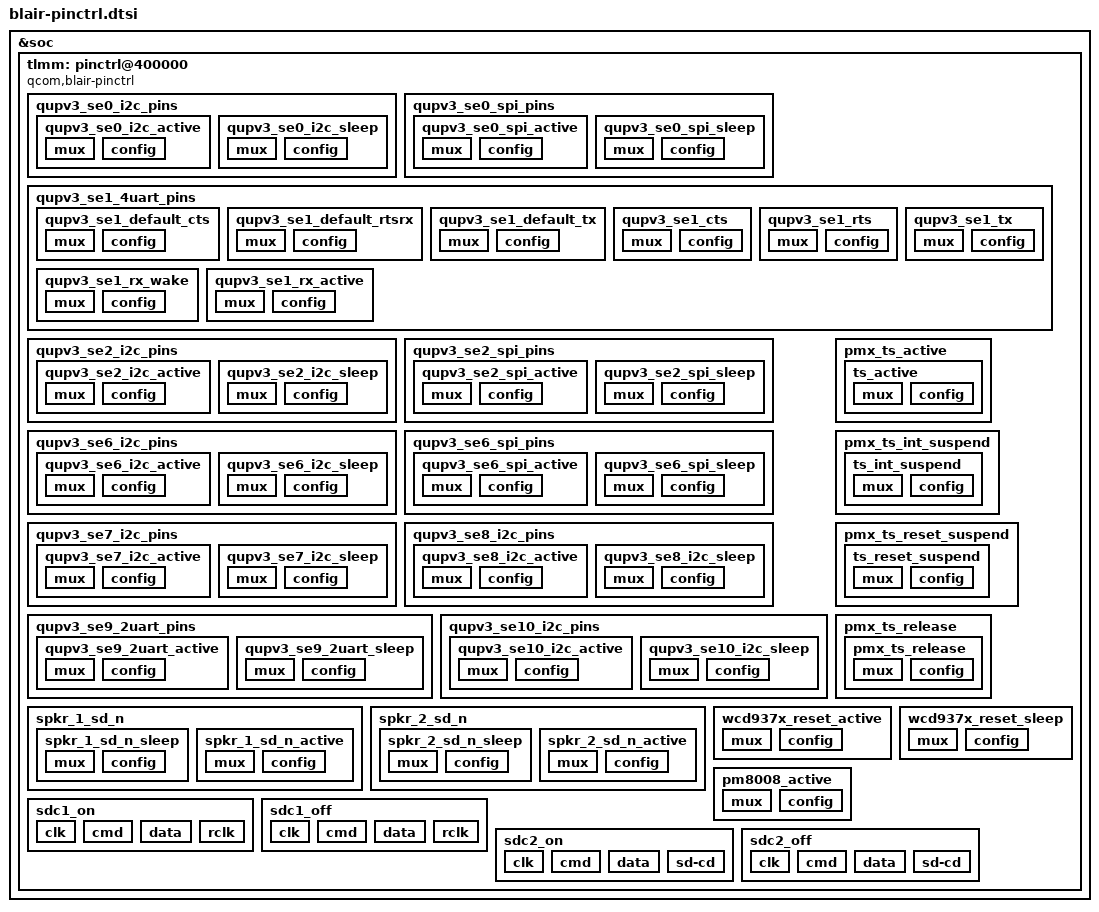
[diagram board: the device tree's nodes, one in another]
&soc {
	tlmm: pinctrl@400000 {
		compatible = "qcom,blair-pinctrl";
		reg = <0x400000 0x800000>;
		interrupts = <GIC_SPI 227 IRQ_TYPE_LEVEL_HIGH>;
		gpio-controller;
		#gpio-cells = <2>;
		interrupt-controller;
		#interrupt-cells = <2>;
		qcom,gpios-reserved = <13 14 15 16 17 45 46 48 56 57>;
		wakeup-parent = <&mpm>;

		qupv3_se0_i2c_pins: qupv3_se0_i2c_pins {
			qupv3_se0_i2c_active: qupv3_se0_i2c_active {
				mux {
					pins = "gpio0", "gpio1";
					function = "qup00";
				};

				config {
					pins = "gpio0", "gpio1";
					drive-strength = <2>;
					bias-pull-up;
				};
			};

			qupv3_se0_i2c_sleep: qupv3_se0_i2c_sleep {
				mux {
					pins = "gpio0", "gpio1";
					function = "gpio";
				};

				config {
					pins = "gpio0", "gpio1";
					drive-strength = <2>;
					bias-disable;
				};
			};
		};

		qupv3_se0_spi_pins: qupv3_se0_spi_pins {
			qupv3_se0_spi_active: qupv3_se0_spi_active {
				mux {
					pins = "gpio0", "gpio1",
							"gpio2", "gpio3";
					function = "qup00";
				};

				config {
					pins = "gpio0", "gpio1",
							"gpio2", "gpio3";
					drive-strength = <6>;
					bias-disable;
				};
			};

			qupv3_se0_spi_sleep: qupv3_se0_spi_sleep {
				mux {
					pins = "gpio0", "gpio1",
							"gpio2", "gpio3";
					function = "gpio";
				};

				config {
					pins = "gpio0", "gpio1",
							"gpio2", "gpio3";
					drive-strength = <2>;
					bias-disable;
				};
			};
		};

		qupv3_se1_4uart_pins: qupv3_se1_4uart_pins {
			qupv3_se1_default_cts:
				qupv3_se1_default_cts {
				mux {
					pins = "gpio61";
					function = "gpio";
				};

				config {
					pins = "gpio61";
					drive-strength = <2>;
					bias-pull-down;
				};
			};

			qupv3_se1_default_rtsrx:
				qupv3_se1_default_rtsrx {
				mux {
					pins = "gpio62", "gpio64";
					function = "gpio";
				};

				config {
					pins = "gpio62", "gpio64";
					drive-strength = <2>;
					bias-pull-down;
				};
			};

			qupv3_se1_default_tx:
				qupv3_se1_default_tx {
				mux {
					pins = "gpio63";
					function = "gpio";
				};

				config {
					pins = "gpio63";
					drive-strength = <2>;
					bias-pull-up;
				};
			};

			qupv3_se1_cts: qupv3_se1_cts {
				mux {
					pins = "gpio61";
					function = "qup01";
				};

				config {
					pins = "gpio61";
					drive-strength = <2>;
					bias-disable;
				};
			};

			qupv3_se1_rts: qupv3_se1_rts {
				mux {
					pins = "gpio62";
					function = "qup01";
				};

				config {
					pins = "gpio62";
					drive-strength = <2>;
					bias-pull-down;
				};
			};

			qupv3_se1_tx: qupv3_se1_tx {
				mux {
					pins = "gpio63";
					function = "qup01";
				};

				config {
					pins = "gpio63";
					drive-strength = <2>;
					bias-pull-up;
				};
			};

			/* RX to be in gpio mode for sleep config */
			qupv3_se1_rx_wake: qupv3_se1_rx_wake {
				mux {
					pins = "gpio64";
					function = "gpio";
				};

				config {
					pins = "gpio64";
					drive-strength = <2>;
					bias-disable;
				};
			};

			qupv3_se1_rx_active: qupv3_se1_rx_active {
				mux {
					pins = "gpio64";
					function = "qup01";
				};

				config {
					pins = "gpio64";
					drive-strength = <2>;
					bias-disable;
				};
			};
		};

		qupv3_se2_i2c_pins: qupv3_se2_i2c_pins {
			qupv3_se2_i2c_active: qupv3_se2_i2c_active {
				mux {
					pins = "gpio45", "gpio46";
					function = "qup02";
				};

				config {
					pins = "gpio45", "gpio46";
					drive-strength = <2>;
					bias-pull-up;
				};
			};

			qupv3_se2_i2c_sleep: qupv3_se2_i2c_sleep {
				mux {
					pins = "gpio45", "gpio46";
					function = "gpio";
				};

				config {
					pins = "gpio45", "gpio46";
					drive-strength = <2>;
					bias-disable;
				};
			};
		};

		qupv3_se2_spi_pins: qupv3_se2_spi_pins {
			qupv3_se2_spi_active: qupv3_se2_spi_active {
				mux {
					pins = "gpio45", "gpio46",
							"gpio56", "gpio57";
					function = "qup02";
				};

				config {
					pins = "gpio45", "gpio46",
							"gpio56", "gpio57";
					drive-strength = <6>;
					bias-disable;
				};
			};

			qupv3_se2_spi_sleep: qupv3_se2_spi_sleep {
				mux {
					pins = "gpio45", "gpio46",
							"gpio56", "gpio57";
					function = "gpio";
				};

				config {
					pins = "gpio45", "gpio46",
							"gpio56", "gpio57";
					drive-strength = <2>;
					bias-disable;
				};
			};
		};

		qupv3_se6_i2c_pins: qupv3_se6_i2c_pins {
			qupv3_se6_i2c_active: qupv3_se6_i2c_active {
				mux {
					pins = "gpio13", "gpio14";
					function = "qup10";
				};

				config {
					pins = "gpio13", "gpio14";
					drive-strength = <2>;
					bias-pull-up;
				};
			};

			qupv3_se6_i2c_sleep: qupv3_se6_i2c_sleep {
				mux {
					pins = "gpio13", "gpio14";
					function = "gpio";
				};

				config {
					pins = "gpio13", "gpio14";
					drive-strength = <2>;
					bias-disable;
				};
			};
		};

		qupv3_se6_spi_pins: qupv3_se6_spi_pins {
			qupv3_se6_spi_active: qupv3_se6_spi_active {
				mux {
					pins = "gpio13", "gpio14",
							"gpio15", "gpio16";
					function = "qup10";
				};

				config {
					pins = "gpio13", "gpio14",
							"gpio15", "gpio16";
					drive-strength = <6>;
					bias-disable;
				};
			};

			qupv3_se6_spi_sleep: qupv3_se6_spi_sleep {
				mux {
					pins = "gpio13", "gpio14",
							"gpio15", "gpio16";
					function = "gpio";
				};

				config {
					pins = "gpio13", "gpio14",
							"gpio15", "gpio16";
					drive-strength = <2>;
					bias-disable;
				};
			};
		};

		qupv3_se7_i2c_pins: qupv3_se7_i2c_pins {
			qupv3_se7_i2c_active: qupv3_se7_i2c_active {
				mux {
					pins = "gpio27", "gpio28";
					function = "qup11_f1";
				};

				config {
					pins = "gpio27", "gpio28";
					drive-strength = <2>;
					bias-pull-up;
				};
			};

			qupv3_se7_i2c_sleep: qupv3_se7_i2c_sleep {
				mux {
					pins = "gpio27", "gpio28";
					function = "gpio";
				};

				config {
					pins = "gpio27", "gpio28";
					drive-strength = <2>;
					bias-disable;
				};
			};
		};

		qupv3_se8_i2c_pins: qupv3_se8_i2c_pins {
			qupv3_se8_i2c_active: qupv3_se8_i2c_active {
				mux {
					pins = "gpio19", "gpio20";
					function = "qup12";
				};

				config {
					pins = "gpio19", "gpio20";
					drive-strength = <2>;
					bias-pull-up;
				};
			};

			qupv3_se8_i2c_sleep: qupv3_se8_i2c_sleep {
				mux {
					pins = "gpio19", "gpio20";
					function = "gpio";
				};

				config {
					pins = "gpio19", "gpio20";
					drive-strength = <2>;
					bias-disable;
				};
			};
		};

		qupv3_se9_2uart_pins: qupv3_se9_2uart_pins {
			qupv3_se9_2uart_active: qupv3_se9_2uart_active {
				mux {
					pins = "gpio25", "gpio26";
					function = "qup13_f2";
				};

				config {
					pins = "gpio25", "gpio26";
					drive-strength = <2>;
					bias-disable;
				};
			};

			qupv3_se9_2uart_sleep: qupv3_se9_2uart_sleep {
				mux {
					pins = "gpio25", "gpio26";
					function = "gpio";
				};

				config {
					pins = "gpio25", "gpio26";
					drive-strength = <2>;
					bias-pull-down;
				};
			};
		};

		qupv3_se10_i2c_pins: qupv3_se10_i2c_pins {
			qupv3_se10_i2c_active: qupv3_se10_i2c_active {
				mux {
					pins = "gpio4", "gpio5";
					function = "qup14";
				};

				config {
					pins = "gpio4", "gpio5";
					drive-strength = <2>;
					bias-pull-up;
				};
			};

			qupv3_se10_i2c_sleep: qupv3_se10_i2c_sleep {
				mux {
					pins = "gpio4", "gpio5";
					function = "gpio";
				};

				config {
					pins = "gpio4", "gpio5";
					drive-strength = <2>;
					bias-disable;
				};
			};
		};

		pmx_ts_active {
			ts_active: ts_active {
				mux {
					pins = "gpio21", "gpio22";
					function = "gpio";
				};

				config {
					pins = "gpio21", "gpio22";
					drive-strength = <8>;
					bias-pull-up;
				};
			};
		};

		pmx_ts_int_suspend {
			ts_int_suspend: ts_int_suspend {
				mux {
					pins = "gpio22";
					function = "gpio";
				};

				config {
					pins = "gpio22";
					drive-strength = <2>;
					bias-pull-down;
				};
			};
		};

		pmx_ts_reset_suspend {
			ts_reset_suspend: ts_reset_suspend {
				mux {
					pins = "gpio21";
					function = "gpio";
				};

				config {
					pins = "gpio21";
					drive-strength = <2>;
					bias-pull-down;
				};
			};
		};

		pmx_ts_release {
			pmx_ts_release: pmx_ts_release {
				mux {
					pins = "gpio21", "gpio22";
					function = "gpio";
				};

				config {
					pins = "gpio21", "gpio22";
					drive-strength = <2>;
					bias-disable;
				};
			};
		};

		/* WSA speaker reset pin */

		spkr_1_sd_n {
			spkr_1_sd_n_sleep: spkr_1_sd_n_sleep {
				mux {
					pins = "gpio86";
					function = "gpio";
				};

				config {
					pins = "gpio86";
					drive-strength = <2>;   /* 2 mA */
					bias-pull-down;
					input-enable;
				};
			};

			spkr_1_sd_n_active: spkr_1_sd_n_active {
				mux {
					pins = "gpio86";
					function = "gpio";
				};

				config {
					pins = "gpio86";
					drive-strength = <16>;   /* 16 mA */
					bias-disable;
					output-high;
				};
			};
		};

		spkr_2_sd_n {
			spkr_2_sd_n_sleep: spkr_2_sd_n_sleep {
				mux {
					pins = "gpio11";
					function = "gpio";
				};

				config {
					pins = "gpio11";
					drive-strength = <2>;   /* 2 mA */
					bias-pull-down;
					input-enable;
				};
			};

			spkr_2_sd_n_active: spkr_2_sd_n_active {
				mux {
					pins = "gpio11";
					function = "gpio";
				};

				config {
					pins = "gpio11";
					drive-strength = <16>;   /* 16 mA */
					bias-disable;
					output-high;
				};
			};
		};

		/* WCD reset pin */
		wcd937x_reset_active: wcd937x_reset_active {
			mux {
				pins = "gpio83";
				function = "gpio";
			};

			config {
				pins = "gpio83";
				drive-strength = <16>;
				output-high;
			};
		};

		wcd937x_reset_sleep: wcd937x_reset_sleep {
			mux {
				pins = "gpio83";
				function = "gpio";
			};

			config {
				pins = "gpio83";
				drive-strength = <16>;
				bias-disable;
				output-low;
			};
		};

		pm8008_active: pm8008_active {
			mux {
				pins = "gpio58";
				function = "gpio";
			};

			config {
				pins = "gpio58";
				bias-pull-up;
				output-high;
				drive-strength = <2>;
			};
		};

		sdc1_on: sdc1_on {
			clk {
				pins = "sdc1_clk";
				bias-disable;
				drive-strength = <16>;
			};

			cmd {
				pins = "sdc1_cmd";
				bias-pull-up;
				drive-strength = <10>;
			};

			data {
				pins = "sdc1_data";
				bias-pull-up;
				drive-strength = <10>;
			};

			rclk {
				pins = "sdc1_rclk";
				bias-pull-down;
			};
		};

		sdc1_off: sdc1_off {
			clk {
				pins = "sdc1_clk";
				bias-disable;
				drive-strength = <2>;
			};

			cmd {
				pins = "sdc1_cmd";
				bias-pull-up;
				drive-strength = <2>;
			};

			data {
				pins = "sdc1_data";
				bias-pull-up;
				drive-strength = <2>;
			};

			rclk {
				pins = "sdc1_rclk";
				bias-pull-down;
			};
		};

		sdc2_on: sdc2_on {
			clk {
				pins = "sdc2_clk";
				bias-disable;
				drive-strength = <16>;
			};

			cmd {
				pins = "sdc2_cmd";
				bias-pull-up;
				drive-strength = <10>;
			};

			data {
				pins = "sdc2_data";
				bias-pull-up;
				drive-strength = <10>;
			};

			sd-cd {
				pins = "gpio94";
				bias-pull-up;
				drive-strength = <2>;
			};
		};

		sdc2_off: sdc2_off {
			clk {
				pins = "sdc2_clk";
				bias-disable;
				drive-strength = <2>;
			};

			cmd {
				pins = "sdc2_cmd";
				bias-pull-up;
				drive-strength = <2>;
			};

			data {
				pins = "sdc2_data";
				bias-pull-up;
				drive-strength = <2>;
			};

			sd-cd {
				pins = "gpio94";
				bias-pull-up;
				drive-strength = <2>;
			};
		};
	};
};
